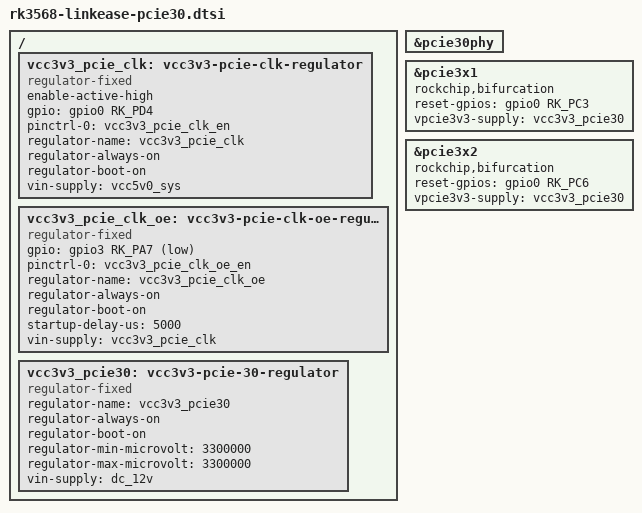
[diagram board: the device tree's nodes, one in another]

/ {
	// VCC3V3_PI6C for PCIE clock power
	vcc3v3_pcie_clk: vcc3v3-pcie-clk-regulator {
		compatible = "regulator-fixed";
		enable-active-high;
		gpio = <&gpio0 RK_PD4 GPIO_ACTIVE_HIGH>;
		pinctrl-names = "default";
		pinctrl-0 = <&vcc3v3_pcie_clk_en>;
		regulator-name = "vcc3v3_pcie_clk";
		regulator-always-on;
		regulator-boot-on;
		vin-supply = <&vcc5v0_sys>;
	};

	// PI6C_OE for PCIE clock enable, active low
	vcc3v3_pcie_clk_oe: vcc3v3-pcie-clk-oe-regulator {
		compatible = "regulator-fixed";
		gpio = <&gpio3 RK_PA7 GPIO_ACTIVE_LOW>;
		pinctrl-names = "default";
		pinctrl-0 = <&vcc3v3_pcie_clk_oe_en>;
		regulator-name = "vcc3v3_pcie_clk_oe";
		regulator-always-on;
		regulator-boot-on;
		startup-delay-us = <5000>;
		vin-supply = <&vcc3v3_pcie_clk>;
	};

	vcc3v3_pcie30: vcc3v3-pcie-30-regulator {
		compatible = "regulator-fixed";
		regulator-name = "vcc3v3_pcie30";
		regulator-always-on;
		regulator-boot-on;
		regulator-min-microvolt = <3300000>;
		regulator-max-microvolt = <3300000>;
		vin-supply = <&dc_12v>;
	};
};

// PCIE3
&pcie30phy {
	status = "okay";
};

/* PCIE3.0_1 */
&pcie3x1 {
	rockchip,bifurcation;
	reset-gpios = <&gpio0 RK_PC3 GPIO_ACTIVE_HIGH>;
	vpcie3v3-supply = <&vcc3v3_pcie30>;
	status = "okay";
};

/* PCIE3.0_2 */
&pcie3x2 {
	rockchip,bifurcation;
	reset-gpios = <&gpio0 RK_PC6 GPIO_ACTIVE_HIGH>;
	vpcie3v3-supply = <&vcc3v3_pcie30>;
	status = "okay";
};
